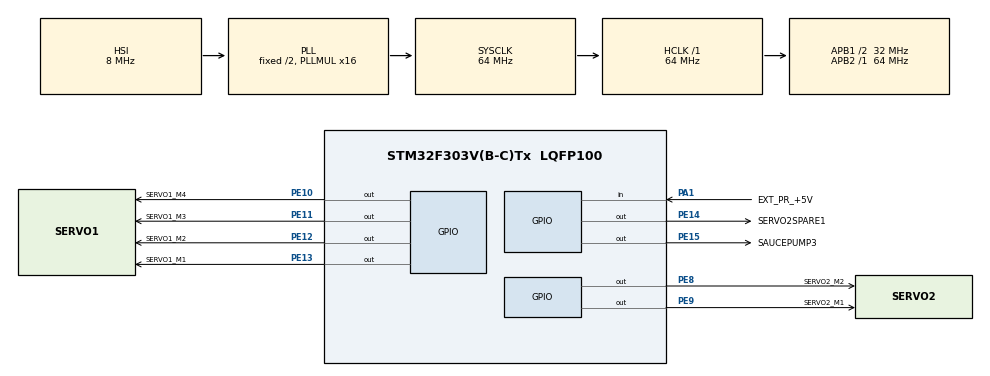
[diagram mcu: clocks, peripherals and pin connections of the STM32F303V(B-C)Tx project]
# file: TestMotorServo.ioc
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FREERTOS.Tasks01=defaultTask,0,128,StartDefaultTask,Default,NULL,Dynamic,NULL,NULL
FREERTOS.Timers01=periodicTimer,PTCallback,osTimerPeriodic,Default,NULL,Dynamic,NULL
FREERTOS.configTIMER_TASK_PRIORITY=6
FREERTOS.configUSE_TIMERS=1
Mcu.Family=STM32F3
Mcu.Name=STM32F303V(B-C)Tx
Mcu.Package=LQFP100
NVIC.PVD_IRQn=true\:5\:0\:true\:false\:true\:true\:true\:true\:true
NVIC.PriorityGroup=NVIC_PRIORITYGROUP_4
PA1.GPIO_Label=EXT_PR_+5V
PA1.GPIO_PuPd=GPIO_PULLUP
PA1.Signal=GPIO_Input
PE10.GPIO_Label=SERVO1_M4
PE10.GPIO_PuPd=GPIO_PULLDOWN
PE10.Signal=GPIO_Output
PE11.GPIO_Label=SERVO1_M3
PE11.GPIO_PuPd=GPIO_PULLDOWN
PE11.Signal=GPIO_Output
PE12.GPIO_Label=SERVO1_M2
PE12.GPIO_PuPd=GPIO_PULLDOWN
PE12.Signal=GPIO_Output
PE13.GPIO_Label=SERVO1_M1
PE13.GPIO_PuPd=GPIO_PULLDOWN
PE13.Signal=GPIO_Output
PE14.GPIO_Label=SERVO2SPARE1
PE14.GPIO_PuPd=GPIO_PULLDOWN
PE14.Signal=GPIO_Output
PE15.GPIO_Label=SAUCEPUMP3
PE15.GPIO_PuPd=GPIO_PULLDOWN
PE15.Signal=GPIO_Output
PE8.GPIO_Label=SERVO2_M2
PE8.GPIO_PuPd=GPIO_PULLDOWN
PE8.Signal=GPIO_Output
PE9.GPIO_Label=SERVO2_M1
PE9.GPIO_PuPd=GPIO_PULLDOWN
PE9.Signal=GPIO_Output
ProjectManager.HeapSize=0x200
ProjectManager.StackSize=0x400
ProjectManager.TargetToolchain=STM32CubeIDE
RCC.AHBFreq_Value=64000000
RCC.APB1CLKDivider=RCC_HCLK_DIV2
RCC.APB1Freq_Value=32000000
RCC.APB1TimFreq_Value=64000000
RCC.APB2Freq_Value=64000000
RCC.APB2TimFreq_Value=64000000
RCC.CortexFreq_Value=64000000
RCC.HCLKFreq_Value=64000000
RCC.HSE_VALUE=8000000
RCC.HSI_VALUE=8000000
RCC.LSE_VALUE=32768
RCC.PLLMUL=RCC_PLL_MUL16
RCC.SYSCLKFreq_VALUE=64000000
RCC.SYSCLKSourceVirtual=RCC_SYSCLKSOURCE_PLLCLK
RCC.USBFreq_Value=64000000
VP_FREERTOS_VS_CMSIS_V1.Mode=CMSIS_V1
board=custom

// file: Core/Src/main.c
/* USER CODE BEGIN Header */
/**
  ******************************************************************************
  * @file           : main.c
  * @brief          : Main program body
  ******************************************************************************
  * @attention
  *
  * Copyright (c) 2022 STMicroelectronics.
  * All rights reserved.
  *
  * This software is licensed under terms that can be found in the LICENSE file
  * in the root directory of this software component.
  * If no LICENSE file comes with this software, it is provided AS-IS.
  *
  ******************************************************************************
  */
/* USER CODE END Header */
#include "main.h"
#include "cmsis_os.h"
#include "gpio.h"

void SystemClock_Config(void);
void MX_FREERTOS_Init(void);

int main(void)
{

  /* MCU Configuration--------------------------------------------------------*/

  /* Reset of all peripherals, Initializes the Flash interface and the Systick. */
  HAL_Init();

  /* Configure the system clock */
  SystemClock_Config();

  /* Initialize all configured peripherals */
  MX_GPIO_Init();

  /* Call init function for freertos objects (in freertos.c) */
  MX_FREERTOS_Init();

  /* Start scheduler */
  osKernelStart();

  /* We should never get here as control is now taken by the scheduler */
  /* Infinite loop */
  while (1)
  {

  }
}

void SystemClock_Config(void)
{
  RCC_OscInitTypeDef RCC_OscInitStruct = {0};
  RCC_ClkInitTypeDef RCC_ClkInitStruct = {0};

  /** Initializes the RCC Oscillators according to the specified parameters
  * in the RCC_OscInitTypeDef structure.
  */
  RCC_OscInitStruct.OscillatorType = RCC_OSCILLATORTYPE_HSI;
  RCC_OscInitStruct.HSIState = RCC_HSI_ON;
  RCC_OscInitStruct.HSICalibrationValue = RCC_HSICALIBRATION_DEFAULT;
  RCC_OscInitStruct.PLL.PLLState = RCC_PLL_ON;
  RCC_OscInitStruct.PLL.PLLSource = RCC_PLLSOURCE_HSI;
  RCC_OscInitStruct.PLL.PLLMUL = RCC_PLL_MUL16;
  if (HAL_RCC_OscConfig(&RCC_OscInitStruct) != HAL_OK)
  {
    Error_Handler();
  }

  /** Initializes the CPU, AHB and APB buses clocks
  */
  RCC_ClkInitStruct.ClockType = RCC_CLOCKTYPE_HCLK|RCC_CLOCKTYPE_SYSCLK
                              |RCC_CLOCKTYPE_PCLK1|RCC_CLOCKTYPE_PCLK2;
  RCC_ClkInitStruct.SYSCLKSource = RCC_SYSCLKSOURCE_PLLCLK;
  RCC_ClkInitStruct.AHBCLKDivider = RCC_SYSCLK_DIV1;
  RCC_ClkInitStruct.APB1CLKDivider = RCC_HCLK_DIV2;
  RCC_ClkInitStruct.APB2CLKDivider = RCC_HCLK_DIV1;

  if (HAL_RCC_ClockConfig(&RCC_ClkInitStruct, FLASH_LATENCY_2) != HAL_OK)
  {
    Error_Handler();
  }
}

void Error_Handler(void)
{
  __disable_irq();
  while (1)
  {
  }
}

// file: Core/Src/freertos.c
/* USER CODE BEGIN Header */
/**
  ******************************************************************************
  * File Name          : freertos.c
  * Description        : Code for freertos applications
  ******************************************************************************
  * @attention
  *
  * Copyright (c) 2022 STMicroelectronics.
  * All rights reserved.
  *
  * This software is licensed under terms that can be found in the LICENSE file
  * in the root directory of this software component.
  * If no LICENSE file comes with this software, it is provided AS-IS.
  *
  ******************************************************************************
  */
/* USER CODE END Header */

#include "FreeRTOS.h"
#include "task.h"
#include "main.h"
#include "cmsis_os.h"

/* USER CODE BEGIN Includes */
#include "appTest.h"
/* USER CODE END Includes */

osThreadId defaultTaskHandle;
osTimerId periodicTimerHandle;

void StartDefaultTask(void const * argument);
void PTCallback(void const * argument);

void MX_FREERTOS_Init(void); /* (MISRA C 2004 rule 8.1) */

/* GetIdleTaskMemory prototype (linked to static allocation support) */
void vApplicationGetIdleTaskMemory( StaticTask_t **ppxIdleTaskTCBBuffer, StackType_t **ppxIdleTaskStackBuffer, uint32_t *pulIdleTaskStackSize );

/* GetTimerTaskMemory prototype (linked to static allocation support) */
void vApplicationGetTimerTaskMemory( StaticTask_t **ppxTimerTaskTCBBuffer, StackType_t **ppxTimerTaskStackBuffer, uint32_t *pulTimerTaskStackSize );

/* USER CODE BEGIN GET_IDLE_TASK_MEMORY */
static StaticTask_t xIdleTaskTCBBuffer;
static StackType_t xIdleStack[configMINIMAL_STACK_SIZE];

void vApplicationGetIdleTaskMemory( StaticTask_t **ppxIdleTaskTCBBuffer, StackType_t **ppxIdleTaskStackBuffer, uint32_t *pulIdleTaskStackSize )
{
  *ppxIdleTaskTCBBuffer = &xIdleTaskTCBBuffer;
  *ppxIdleTaskStackBuffer = &xIdleStack[0];
  *pulIdleTaskStackSize = configMINIMAL_STACK_SIZE;
  /* place for user code */
}
/* USER CODE END GET_IDLE_TASK_MEMORY */

/* USER CODE BEGIN GET_TIMER_TASK_MEMORY */
static StaticTask_t xTimerTaskTCBBuffer;
static StackType_t xTimerStack[configTIMER_TASK_STACK_DEPTH];

void vApplicationGetTimerTaskMemory( StaticTask_t **ppxTimerTaskTCBBuffer, StackType_t **ppxTimerTaskStackBuffer, uint32_t *pulTimerTaskStackSize )
{
  *ppxTimerTaskTCBBuffer = &xTimerTaskTCBBuffer;
  *ppxTimerTaskStackBuffer = &xTimerStack[0];
  *pulTimerTaskStackSize = configTIMER_TASK_STACK_DEPTH;
  /* place for user code */
}
/* USER CODE END GET_TIMER_TASK_MEMORY */

void MX_FREERTOS_Init(void) {

  /* Create the timer(s) */
  /* definition and creation of periodicTimer */
  osTimerDef(periodicTimer, PTCallback);
  periodicTimerHandle = osTimerCreate(osTimer(periodicTimer), osTimerPeriodic, NULL);

  /* Create the thread(s) */
  /* definition and creation of defaultTask */
  osThreadDef(defaultTask, StartDefaultTask, osPriorityNormal, 0, 128);
  defaultTaskHandle = osThreadCreate(osThread(defaultTask), NULL);

}

void StartDefaultTask(void const * argument)
{
  /* USER CODE BEGIN StartDefaultTask */
  AppTest_Init();
  osTimerStart(periodicTimerHandle, 1000);
  /* Infinite loop */
  for(;;)
  {
	  AppTest_Loop();
	  //osDelay(1);
  }
  /* USER CODE END StartDefaultTask */
}

/* PTCallback function */
void PTCallback(void const * argument)
{
  /* USER CODE BEGIN PTCallback */
  AppTest_CallEachSecond();
  /* USER CODE END PTCallback */
}
